# LM3S9B96 register map
File version: 7944
Registers are 32-bit, read-write, no defined reset value unless marked. A register's access mark holds for its fields unless they carry their own. Offsets are from the block's base; [hi:lo] are bit positions; {n}, {i} and the like mark numbered series.

## I2S0 — Register map for I2S0 peripheral
Base 0x40054000; register names take the prefix I2S0
0x00 TXFIFO wo — I2S Transmit FIFO Data
  [31:0] I2S_TXFIFO — TX Data
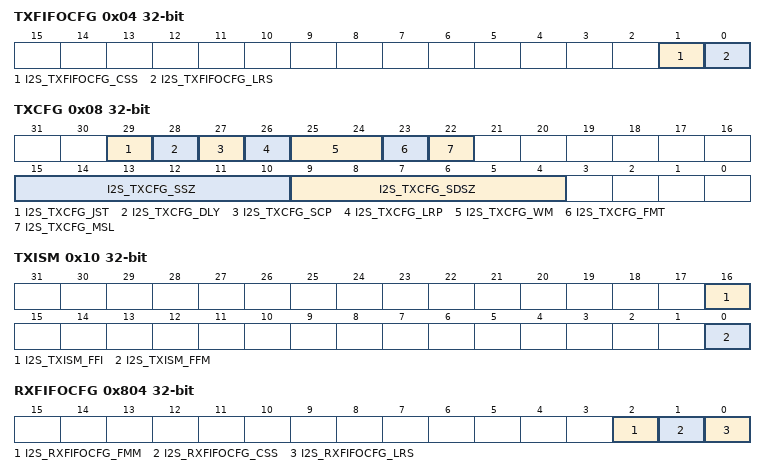
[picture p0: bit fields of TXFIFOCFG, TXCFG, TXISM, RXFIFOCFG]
0x04 TXFIFOCFG — I2S Transmit FIFO Configuration
  [1] I2S_TXFIFOCFG_CSS — Compact Stereo Sample Size
  [0] I2S_TXFIFOCFG_LRS — Left-Right Sample Indicator
0x08 TXCFG — I2S Transmit Module Configuration
  [29] I2S_TXCFG_JST — Justification of Output Data
  [28] I2S_TXCFG_DLY — Data Delay
  [27] I2S_TXCFG_SCP — SCLK Polarity
  [26] I2S_TXCFG_LRP — Left/Right Clock Polarity
  [25:24] I2S_TXCFG_WM — Write Mode
    0=I2S_TXCFG_WM_DUAL (Stereo mode); 1=I2S_TXCFG_WM_COMPACT (Compact Stereo mode); 2=I2S_TXCFG_WM_MONO (Mono mode)
  [23] I2S_TXCFG_FMT — FIFO Empty
  [22] I2S_TXCFG_MSL — SCLK Master/Slave
  [15:10] I2S_TXCFG_SSZ — Sample Size
  [9:4] I2S_TXCFG_SDSZ — System Data Size
0x0C TXLIMIT — I2S Transmit FIFO Limit
  [4:0] I2S_TXLIMIT_LIMIT — FIFO Limit
0x10 TXISM — I2S Transmit Interrupt Status and Mask
  [16] I2S_TXISM_FFI — Transmit FIFO Service Request Interrupt
  [0] I2S_TXISM_FFM — FIFO Interrupt Mask
0x18 TXLEV — I2S Transmit FIFO Level
  [4:0] I2S_TXLEV_LEVEL — Number of Audio Samples
0x800 RXFIFO — I2S Receive FIFO Data
  [31:0] I2S_RXFIFO — RX Data
0x804 RXFIFOCFG — I2S Receive FIFO Configuration
  [2] I2S_RXFIFOCFG_FMM — FIFO Mono Mode
  [1] I2S_RXFIFOCFG_CSS — Compact Stereo Sample Size
  [0] I2S_RXFIFOCFG_LRS — Left-Right Sample Indicator
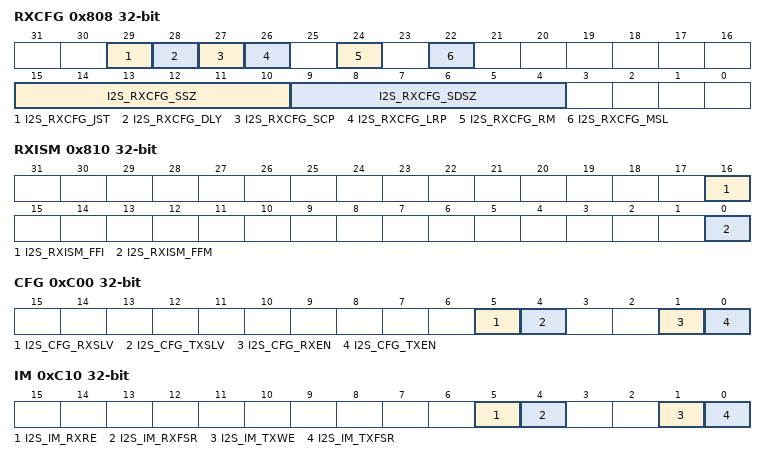
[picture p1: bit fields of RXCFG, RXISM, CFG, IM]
0x808 RXCFG — I2S Receive Module Configuration
  [29] I2S_RXCFG_JST — Justification of Input Data
  [28] I2S_RXCFG_DLY — Data Delay
  [27] I2S_RXCFG_SCP — SCLK Polarity
  [26] I2S_RXCFG_LRP — Left/Right Clock Polarity
  [24] I2S_RXCFG_RM — Read Mode
  [22] I2S_RXCFG_MSL — SCLK Master/Slave
  [15:10] I2S_RXCFG_SSZ — Sample Size
  [9:4] I2S_RXCFG_SDSZ — System Data Size
0x80C RXLIMIT — I2S Receive FIFO Limit
  [4:0] I2S_RXLIMIT_LIMIT — FIFO Limit
0x810 RXISM — I2S Receive Interrupt Status and Mask
  [16] I2S_RXISM_FFI — Receive FIFO Service Request Interrupt
  [0] I2S_RXISM_FFM — FIFO Interrupt Mask
0x818 RXLEV — I2S Receive FIFO Level
  [4:0] I2S_RXLEV_LEVEL — Number of Audio Samples
0xC00 CFG — I2S Module Configuration
  [5] I2S_CFG_RXSLV — Use External I2S0RXMCLK
  [4] I2S_CFG_TXSLV — Use External I2S0TXMCLK
  [1] I2S_CFG_RXEN — Serial Receive Engine Enable
  [0] I2S_CFG_TXEN — Serial Transmit Engine Enable
0xC10 IM — I2S Interrupt Mask
  [5] I2S_IM_RXRE — Receive FIFO Read Error
  [4] I2S_IM_RXFSR — Receive FIFO Service Request
  [1] I2S_IM_TXWE — Transmit FIFO Write Error
  [0] I2S_IM_TXFSR — Transmit FIFO Service Request
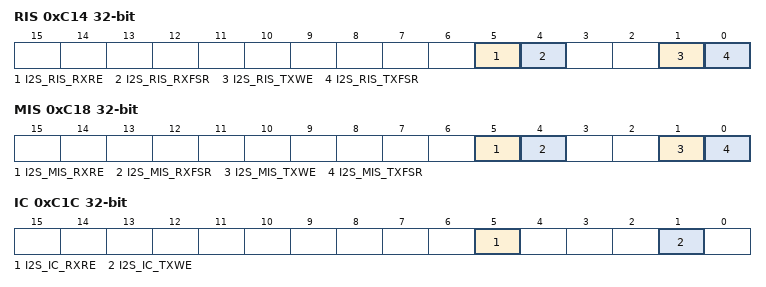
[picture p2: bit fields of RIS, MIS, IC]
0xC14 RIS — I2S Raw Interrupt Status
  [5] I2S_RIS_RXRE — Receive FIFO Read Error
  [4] I2S_RIS_RXFSR — Receive FIFO Service Request
  [1] I2S_RIS_TXWE — Transmit FIFO Write Error
  [0] I2S_RIS_TXFSR — Transmit FIFO Service Request
0xC18 MIS — I2S Masked Interrupt Status
  [5] I2S_MIS_RXRE — Receive FIFO Read Error
  [4] I2S_MIS_RXFSR — Receive FIFO Service Request
  [1] I2S_MIS_TXWE — Transmit FIFO Write Error
  [0] I2S_MIS_TXFSR — Transmit FIFO Service Request
0xC1C IC wo — I2S Interrupt Clear
  [5] I2S_IC_RXRE — Receive FIFO Read Error
  [1] I2S_IC_TXWE — Transmit FIFO Write Error

## FLASH_CTRL — Register map for FLASH_CTRL peripheral
Base 0x400FD000; register names take the prefix FLASH_CTRL
0x00 FMA — Flash Memory Address
  [17:0] FLASH_FMA_OFFSET — Address Offset
0x04 FMD — Flash Memory Data
  [31:0] FLASH_FMD_DATA — Data Value
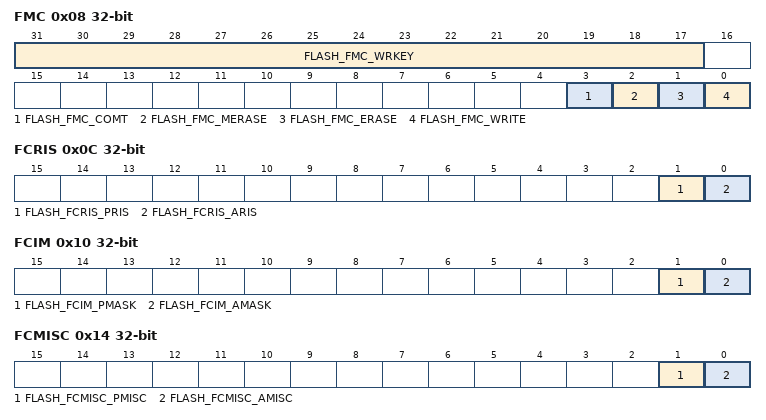
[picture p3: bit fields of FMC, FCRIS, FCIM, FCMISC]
0x08 FMC — Flash Memory Control
  [31:17] FLASH_FMC_WRKEY — FLASH write key
  [3] FLASH_FMC_COMT — Commit Register Value
  [2] FLASH_FMC_MERASE — Mass Erase Flash Memory
  [1] FLASH_FMC_ERASE — Erase a Page of Flash Memory
  [0] FLASH_FMC_WRITE — Write a Word into Flash Memory
0x0C FCRIS — Flash Controller Raw Interrupt Status
  [1] FLASH_FCRIS_PRIS — Programming Raw Interrupt Status
  [0] FLASH_FCRIS_ARIS — Access Raw Interrupt Status
0x10 FCIM — Flash Controller Interrupt Mask
  [1] FLASH_FCIM_PMASK — Programming Interrupt Mask
  [0] FLASH_FCIM_AMASK — Access Interrupt Mask
0x14 FCMISC — Flash Controller Masked Interrupt Status and Clear
  [1] FLASH_FCMISC_PMISC — Programming Masked Interrupt Status and Clear
  [0] FLASH_FCMISC_AMISC — Access Masked Interrupt Status and Clear
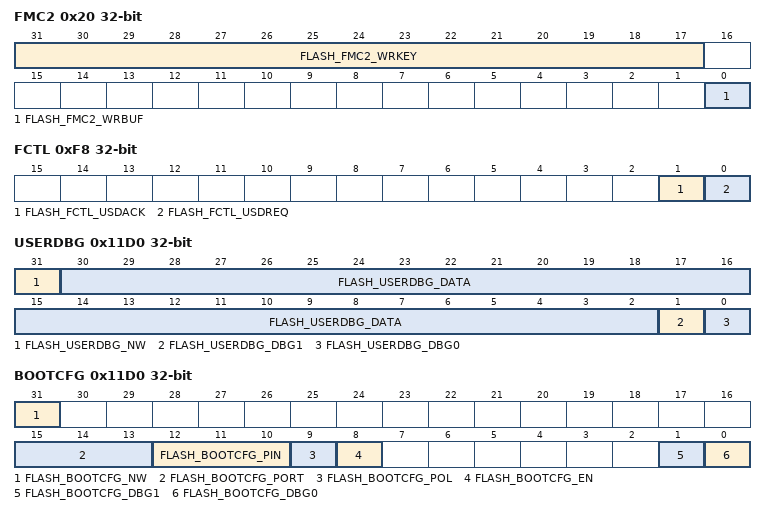
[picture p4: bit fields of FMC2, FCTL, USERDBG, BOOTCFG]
0x20 FMC2 — Flash Memory Control 2
  [31:17] FLASH_FMC2_WRKEY — FLASH write key
  [0] FLASH_FMC2_WRBUF — Buffered Flash Memory Write
0x30 FWBVAL — Flash Write Buffer Valid
  [31:0] FLASH_FWBVAL_FWB — Flash Memory Write Buffer
0xF8 FCTL — Flash Control
  [1] FLASH_FCTL_USDACK — User Shut Down Acknowledge
  [0] FLASH_FCTL_USDREQ — User Shut Down Request
0x100 FWBN — Flash Write Buffer n
  [31:0] FLASH_FWBN_DATA — Data
0x10F0 RMCTL — ROM Control
  [0] FLASH_RMCTL_BA — Boot Alias
0x11D0 USERDBG (FLASH_ALT view) — User Debug
  [31] FLASH_USERDBG_NW — User Debug Not Written
  [30:2] FLASH_USERDBG_DATA — User Data
  [1] FLASH_USERDBG_DBG1 — Debug Control 1
  [0] FLASH_USERDBG_DBG0 — Debug Control 0
0x11D0 BOOTCFG — Boot Configuration
  [31] FLASH_BOOTCFG_NW — Not Written
  [15:13] FLASH_BOOTCFG_PORT — Boot GPIO Port
    0=FLASH_BOOTCFG_PORT_A (Port A); 1=FLASH_BOOTCFG_PORT_B (Port B); 2=FLASH_BOOTCFG_PORT_C (Port C); 3=FLASH_BOOTCFG_PORT_D (Port D); 4=FLASH_BOOTCFG_PORT_E (Port E); 5=FLASH_BOOTCFG_PORT_F (Port F); 6=FLASH_BOOTCFG_PORT_G (Port G); 7=FLASH_BOOTCFG_PORT_H (Port H)
  [12:10] FLASH_BOOTCFG_PIN — Boot GPIO Pin
    {v}=Pin {v} (v=0..7)
  [9] FLASH_BOOTCFG_POL — Boot GPIO Polarity
  [8] FLASH_BOOTCFG_EN — Boot GPIO Enable
  [1] FLASH_BOOTCFG_DBG1 — Debug Control 1
  [0] FLASH_BOOTCFG_DBG0 — Debug Control 0
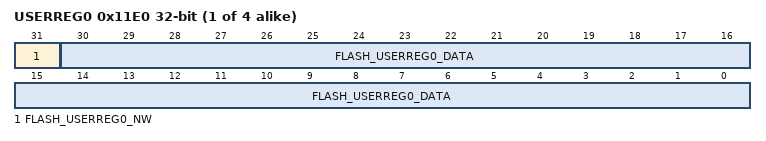
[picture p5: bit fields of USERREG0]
{0x11E0+4i} USERREG{i} (i=0..3) — User Register {i}
  [31] FLASH_USERREG{i}_NW — Not Written
  [30:0] FLASH_USERREG{i}_DATA — User Data
{0x1200+4i} FMPRE{i} (i=0..3) — Flash Memory Protection Read Enable {i}
{0x1400+4i} FMPPE{i} (i=0..3) — Flash Memory Protection Program Enable {i}

## UDMA — Register map for UDMA peripheral
Base 0x400FF000; register names take the prefix UDMA
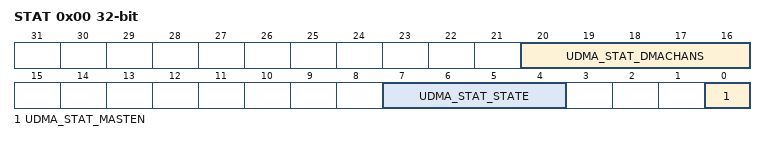
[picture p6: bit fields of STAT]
0x00 STAT — DMA Status
  [20:16] UDMA_STAT_DMACHANS — Available uDMA Channels Minus 1
  [7:4] UDMA_STAT_STATE — Control State Machine Status
    0=UDMA_STAT_STATE_IDLE (Idle); 1=UDMA_STAT_STATE_RD_CTRL (Reading channel controller data); 2=UDMA_STAT_STATE_RD_SRCENDP (Reading source end pointer); 3=UDMA_STAT_STATE_RD_DSTENDP (Reading destination end pointer); 4=UDMA_STAT_STATE_RD_SRCDAT (Reading source data); 5=UDMA_STAT_STATE_WR_DSTDAT (Writing destination data); 6=UDMA_STAT_STATE_WAIT (Waiting for uDMA request to clear); 7=UDMA_STAT_STATE_WR_CTRL (Writing channel controller data); 8=UDMA_STAT_STATE_STALL (Stalled); 9=UDMA_STAT_STATE_DONE (Done); 10=UDMA_STAT_STATE_UNDEF (Undefined)
  [0] UDMA_STAT_MASTEN — Master Enable Status
0x04 CFG wo — DMA Configuration
  [0] UDMA_CFG_MASTEN — Controller Master Enable
0x08 CTLBASE — DMA Channel Control Base Pointer
  [31:10] UDMA_CTLBASE_ADDR — Channel Control Base Address
0x0C ALTBASE — DMA Alternate Channel Control Base Pointer
  [31:0] UDMA_ALTBASE_ADDR — Alternate Channel Address Pointer
0x10 WAITSTAT — DMA Channel Wait-on-Request Status
  [31:0] UDMA_WAITSTAT_WAITREQ — Channel [n] Wait Status
0x14 SWREQ wo — DMA Channel Software Request
  [31:0] UDMA_SWREQ — Channel [n] Software Request
0x18 USEBURSTSET — DMA Channel Useburst Set
  [31:0] UDMA_USEBURSTSET_SET — Channel [n] Useburst Set
0x1C USEBURSTCLR wo — DMA Channel Useburst Clear
  [31:0] UDMA_USEBURSTCLR_CLR — Channel [n] Useburst Clear
0x20 REQMASKSET — DMA Channel Request Mask Set
  [31:0] UDMA_REQMASKSET_SET — Channel [n] Request Mask Set
0x24 REQMASKCLR wo — DMA Channel Request Mask Clear
  [31:0] UDMA_REQMASKCLR_CLR — Channel [n] Request Mask Clear
0x28 ENASET — DMA Channel Enable Set
  [31:0] UDMA_ENASET_SET — Channel [n] Enable Set
0x2C ENACLR wo — DMA Channel Enable Clear
  [31:0] UDMA_ENACLR_CLR — Clear Channel [n] Enable Clear
0x30 ALTSET — DMA Channel Primary Alternate Set
  [31:0] UDMA_ALTSET_SET — Channel [n] Alternate Set
0x34 ALTCLR wo — DMA Channel Primary Alternate Clear
  [31:0] UDMA_ALTCLR_CLR — Channel [n] Alternate Clear
0x38 PRIOSET — DMA Channel Priority Set
  [31:0] UDMA_PRIOSET_SET — Channel [n] Priority Set
0x3C PRIOCLR wo — DMA Channel Priority Clear
  [31:0] UDMA_PRIOCLR_CLR — Channel [n] Priority Clear
0x4C ERRCLR — DMA Bus Error Clear
  [0] UDMA_ERRCLR_ERRCLR — uDMA Bus Error Status
0x500 CHASGN — DMA Channel Assignment
  [31:0] UDMA_CHASGN — Channel [n] Assignment Select
    0=UDMA_CHASGN_PRIMARY (Use the primary channel assignment); 1=UDMA_CHASGN_SECONDARY (Use the secondary channel assignment)
